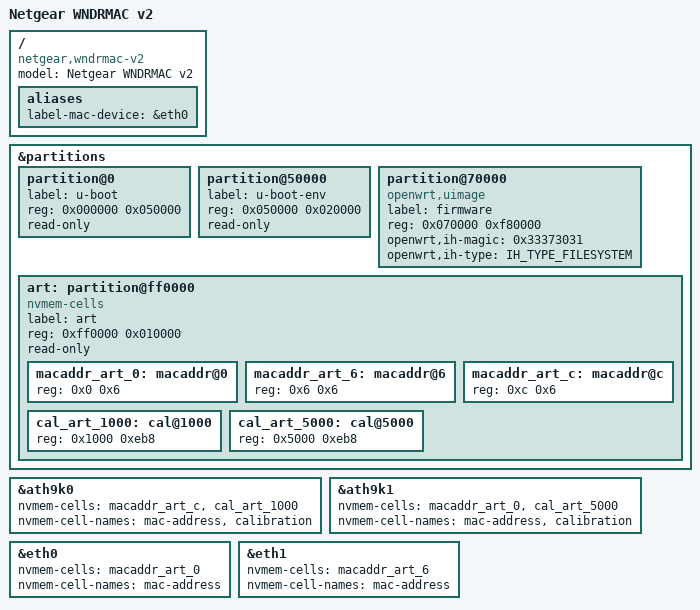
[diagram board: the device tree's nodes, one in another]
// SPDX-License-Identifier: GPL-2.0-or-later OR MIT

#include "ar7161_netgear_wndr.dtsi"

/ {
	compatible = "netgear,wndrmac-v2", "qca,ar7161";
	model = "Netgear WNDRMAC v2";

	aliases {
		label-mac-device = &eth0;
	};
};

&partitions {
	partition@0 {
		label = "u-boot";
		reg = <0x000000 0x050000>;
		read-only;
	};

	partition@50000 {
		label = "u-boot-env";
		reg = <0x050000 0x020000>;
		read-only;
	};

	partition@70000 {
		label = "firmware";
		reg = <0x070000 0xf80000>;
		compatible = "openwrt,uimage", "denx,uimage";
		openwrt,ih-magic = <0x33373031>;
		openwrt,ih-type = <IH_TYPE_FILESYSTEM>;
	};

	art: partition@ff0000 {
		label = "art";
		reg = <0xff0000 0x010000>;
		read-only;
	};
};

&ath9k0 {
	nvmem-cells = <&macaddr_art_c>, <&cal_art_1000>;
	nvmem-cell-names = "mac-address", "calibration";
};

&ath9k1 {
	nvmem-cells = <&macaddr_art_0>, <&cal_art_5000>;
	nvmem-cell-names = "mac-address", "calibration";
};

&eth0 {
	nvmem-cells = <&macaddr_art_0>;
	nvmem-cell-names = "mac-address";
};

&eth1 {
	nvmem-cells = <&macaddr_art_6>;
	nvmem-cell-names = "mac-address";
};

&art {
	compatible = "nvmem-cells";
	#address-cells = <1>;
	#size-cells = <1>;

	macaddr_art_0: macaddr@0 {
		reg = <0x0 0x6>;
	};

	macaddr_art_6: macaddr@6 {
		reg = <0x6 0x6>;
	};

	macaddr_art_c: macaddr@c {
		reg = <0xc 0x6>;
	};

	cal_art_1000: cal@1000 {
		reg = <0x1000 0xeb8>;
	};

	cal_art_5000: cal@5000 {
		reg = <0x5000 0xeb8>;
	};
};
